VERSION ""

NS_ :

BS_:

BU_: XXX

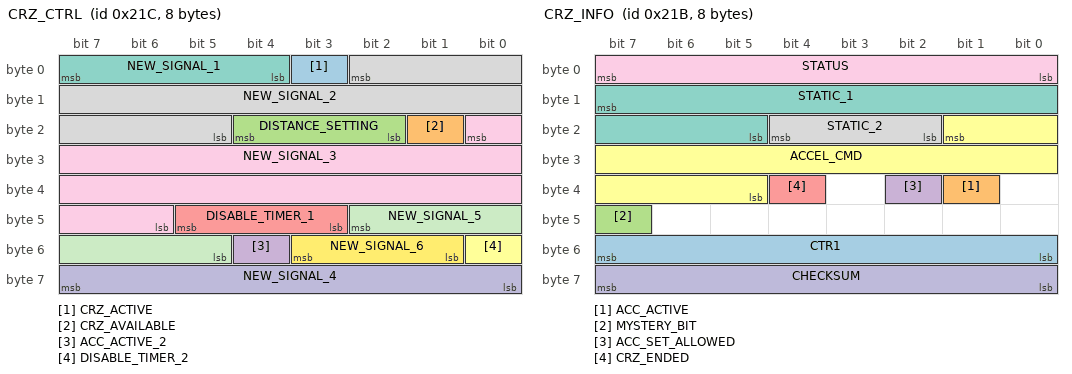
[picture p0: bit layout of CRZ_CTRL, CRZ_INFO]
BO_ 540 CRZ_CTRL: 8 XXX
 SG_ CRZ_ACTIVE : 3|1@0+ (1,0) [0|1] "" XXX
 SG_ CRZ_AVAILABLE : 17|1@0+ (1,0) [0|255] "" XXX
 SG_ DISTANCE_SETTING : 20|3@0+ (1,0) [0|7] "" XXX
 SG_ ACC_ACTIVE_2 : 52|1@0+ (1,0) [0|1] "" XXX
 SG_ DISABLE_TIMER_1 : 43|3@1+ (1,0) [0|7] "" XXX
 SG_ DISABLE_TIMER_2 : 48|1@0+ (1,0) [0|1] "" XXX
 SG_ NEW_SIGNAL_1 : 7|4@0+ (1,0) [0|15] "" XXX
 SG_ NEW_SIGNAL_2 : 2|14@0+ (1,0) [0|1] "" XXX
 SG_ NEW_SIGNAL_3 : 16|19@0+ (1,0) [0|1] "" XXX
 SG_ NEW_SIGNAL_4 : 63|8@0+ (1,0) [0|3] "" XXX
 SG_ NEW_SIGNAL_5 : 42|6@0+ (1,0) [0|3] "" XXX
 SG_ NEW_SIGNAL_6 : 49|3@1+ (1,0) [0|3] "" XXX

BO_ 539 CRZ_INFO: 8 XXX
 SG_ CTR1 : 55|8@0+ (1,0) [0|255] "" XXX
 SG_ ACC_ACTIVE : 33|1@0+ (1,0) [0|1] "" XXX
 SG_ MYSTERY_BIT : 47|1@0+ (1,0) [0|255] "" XXX
 SG_ ACC_SET_ALLOWED : 34|1@0+ (1,0) [0|1] "" XXX
 SG_ CRZ_ENDED : 36|1@0+ (1,0) [0|255] "" XXX
 SG_ ACCEL_CMD : 17|13@0+ (1,-4096) [0|8191] "" XXX
 SG_ STATIC_1 : 15|11@0+ (1,0) [0|2047] "" XXX
 SG_ STATIC_2 : 18|3@1+ (1,0) [0|7] "" XXX
 SG_ STATUS : 7|8@0+ (1,0) [0|255] "" XXX
 SG_ CHECKSUM : 56|8@1+ (1,0) [0|255] "" XXX

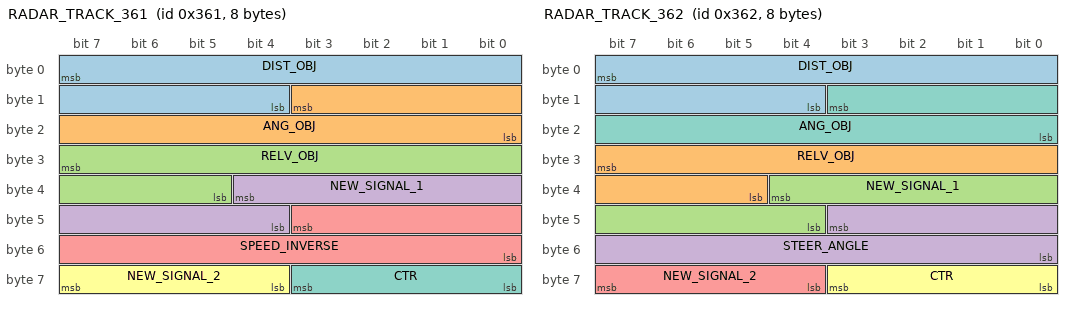
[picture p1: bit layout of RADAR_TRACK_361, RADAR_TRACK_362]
BO_ 865 RADAR_TRACK_361: 8 XXX
 SG_ DIST_OBJ : 7|12@0+ (1,0) [0|31] "" XXX
 SG_ ANG_OBJ : 11|12@0- (1,0) [0|255] "" XXX
 SG_ RELV_OBJ : 31|11@0- (1,0) [0|255] "" XXX
 SG_ NEW_SIGNAL_1 : 36|9@0+ (1,0) [0|3] "" XXX
 SG_ SPEED_INVERSE : 43|12@0- (-0.225,0) [0|255] "kph" XXX
 SG_ NEW_SIGNAL_2 : 63|4@0+ (1,0) [0|15] "" XXX
 SG_ CTR : 56|4@1+ (1,0) [0|15] "" XXX

BO_ 866 RADAR_TRACK_362: 8 XXX
 SG_ DIST_OBJ : 7|12@0+ (1,0) [0|255] "" XXX
 SG_ RELV_OBJ : 31|11@0- (1,0) [0|63] "" XXX
 SG_ NEW_SIGNAL_1 : 36|9@0+ (1,0) [0|3] "" XXX
 SG_ STEER_ANGLE : 43|12@0+ (-1,2048) [0|7] "" XXX
 SG_ NEW_SIGNAL_2 : 63|4@0+ (1,0) [0|15] "" XXX
 SG_ CTR : 59|4@0+ (1,0) [0|15] "" XXX
 SG_ ANG_OBJ : 11|12@0- (1,0) [0|7] "" XXX

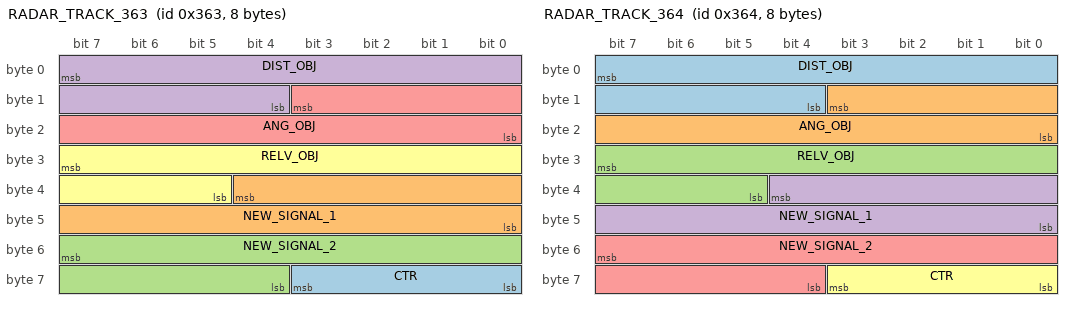
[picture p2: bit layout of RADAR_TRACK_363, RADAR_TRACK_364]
BO_ 867 RADAR_TRACK_363: 8 XXX
 SG_ CTR : 59|4@0+ (1,0) [0|255] "" XXX
 SG_ NEW_SIGNAL_1 : 36|13@0+ (1,0) [0|7] "" XXX
 SG_ NEW_SIGNAL_2 : 55|12@0+ (1,0) [0|7] "" XXX
 SG_ DIST_OBJ : 7|12@0+ (1,0) [0|131071] "" XXX
 SG_ ANG_OBJ : 11|12@0- (1,0) [0|127] "" XXX
 SG_ RELV_OBJ : 31|11@0- (1,0) [0|63] "" XXX

BO_ 868 RADAR_TRACK_364: 8 XXX
 SG_ DIST_OBJ : 7|12@0+ (1,0) [0|131071] "" XXX
 SG_ ANG_OBJ : 11|12@0- (1,0) [0|127] "" XXX
 SG_ RELV_OBJ : 31|11@0- (1,0) [0|63] "" XXX
 SG_ NEW_SIGNAL_1 : 36|13@0+ (1,0) [0|3] "" XXX
 SG_ NEW_SIGNAL_2 : 55|12@0+ (1,0) [0|7] "" XXX
 SG_ CTR : 59|4@0+ (1,0) [0|255] "" XXX

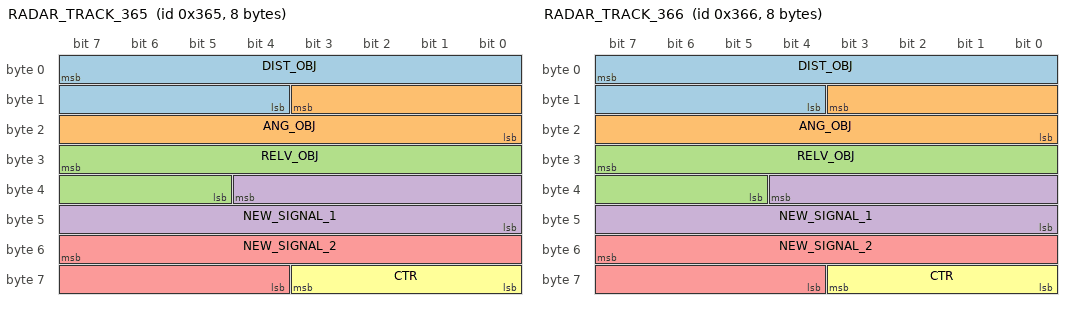
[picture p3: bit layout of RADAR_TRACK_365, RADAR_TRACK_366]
BO_ 869 RADAR_TRACK_365: 8 XXX
 SG_ DIST_OBJ : 7|12@0+ (1,0) [0|131071] "" XXX
 SG_ ANG_OBJ : 11|12@0- (1,0) [0|127] "" XXX
 SG_ RELV_OBJ : 31|11@0- (1,0) [0|63] "" XXX
 SG_ NEW_SIGNAL_1 : 36|13@0+ (1,0) [0|3] "" XXX
 SG_ NEW_SIGNAL_2 : 55|12@0+ (1,0) [0|7] "" XXX
 SG_ CTR : 59|4@0+ (1,0) [0|255] "" XXX

BO_ 870 RADAR_TRACK_366: 8 XXX
 SG_ DIST_OBJ : 7|12@0+ (1,0) [0|131071] "" XXX
 SG_ ANG_OBJ : 11|12@0- (1,0) [0|127] "" XXX
 SG_ RELV_OBJ : 31|11@0- (1,0) [0|63] "" XXX
 SG_ NEW_SIGNAL_1 : 36|13@0+ (1,0) [0|3] "" XXX
 SG_ NEW_SIGNAL_2 : 55|12@0+ (1,0) [0|7] "" XXX
 SG_ CTR : 59|4@0+ (1,0) [0|255] "" XXX

BO_ 1177 RADAR_499: 8 XXX
